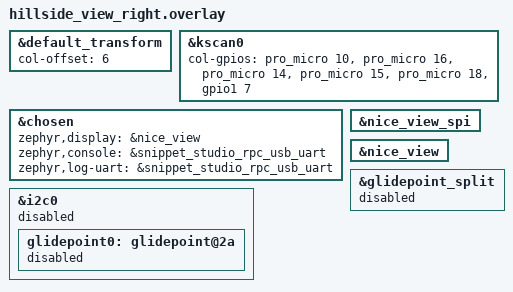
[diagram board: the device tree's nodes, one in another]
/*
 * Copyright (c) 2022 The ZMK Contributors
 *
 * SPDX-License-Identifier: MIT
 */

#include "hillside_view.dtsi"

&default_transform {
  col-offset = <6>;
};

&kscan0 {
  col-gpios
    = <&pro_micro 10 GPIO_ACTIVE_HIGH>
    , <&pro_micro 16 GPIO_ACTIVE_HIGH>
    , <&pro_micro 14 GPIO_ACTIVE_HIGH>
    , <&pro_micro 15 GPIO_ACTIVE_HIGH>
    , <&pro_micro 18 GPIO_ACTIVE_HIGH>
    , <&gpio1 7 GPIO_ACTIVE_HIGH>
    ;
};

// &right_encoder {
//   status = "okay";
// };

// trackball bus
/* &spi0 { */
/*   status = "okay"; */
/*   sck-pin = <20>; */
/*   mosi-pin = <17>; */
/*   miso-pin = <17>; // same as mosi (3-wire spi) */
/*   cs-gpios = <&gpio0 22 GPIO_ACTIVE_LOW>; */
/* }; */

/* &trackball { */
/*   status = "okay"; */
/*   irq-gpios = <&gpio0 24 (GPIO_ACTIVE_LOW | GPIO_PULL_UP)>; */
/* }; */


&chosen {
  zephyr,display = &nice_view;
  zephyr,console = &snippet_studio_rpc_usb_uart;
  zephyr,log-uart = &snippet_studio_rpc_usb_uart;
};

&nice_view_spi {
  status = "okay";
};

&nice_view {
  status = "okay";
};

&i2c0 {
  status = "disabled";
  glidepoint0: glidepoint@2a {
      status = "disabled";
  };
};

// Trackpad is not installed yet on this half; keep split input on shared default.
&glidepoint_split {
  status = "disabled";
};
